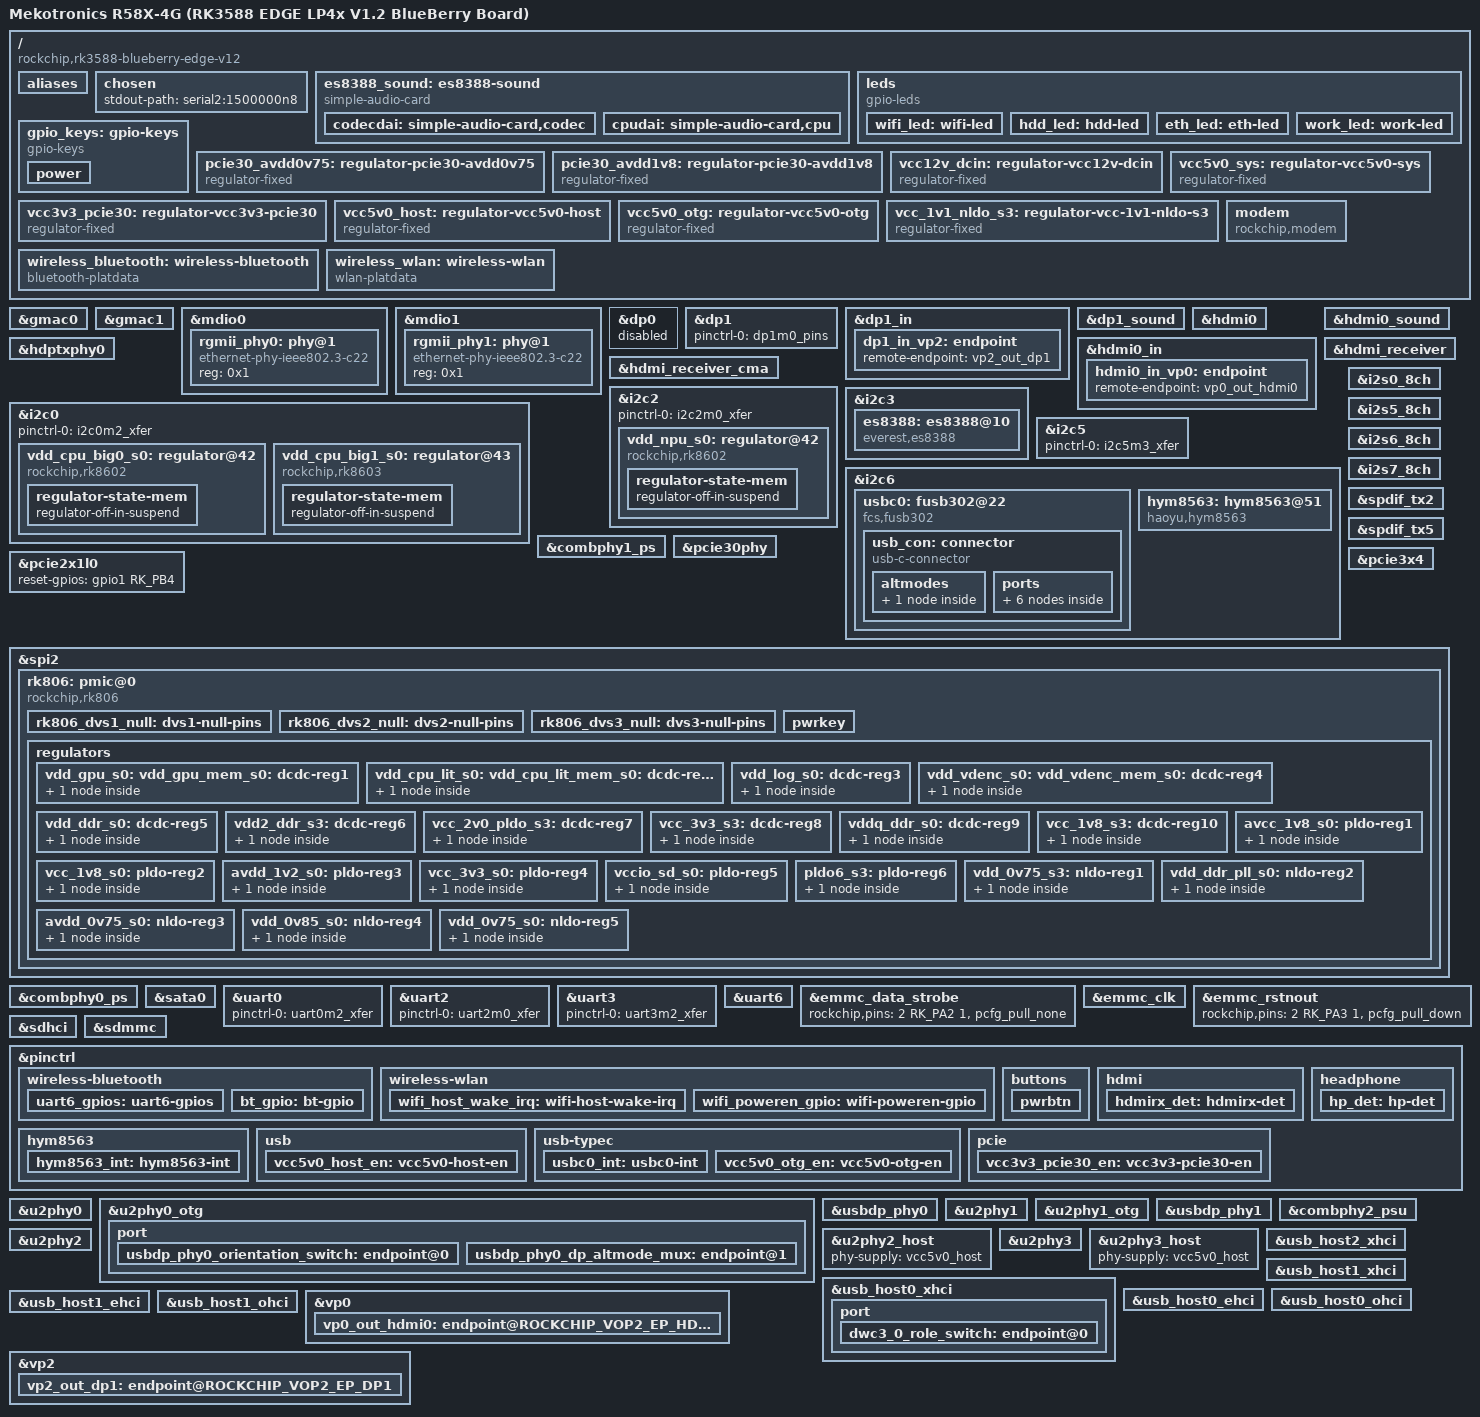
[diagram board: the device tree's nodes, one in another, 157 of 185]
// SPDX-License-Identifier: (GPL-2.0+ OR MIT)
/*
 * Copyright (c) 2026 Valentin Liu <valentinliu@icloud.com>
 */

/dts-v1/;

#include <dt-bindings/soc/rockchip,vop2.h>
#include "rk3588-blueberry.dtsi"

/ {	
	model = "Mekotronics R58X-4G (RK3588 EDGE LP4x V1.2 BlueBerry Board)";
	compatible = "rockchip,rk3588-blueberry-edge-v12", "rockchip,rk3588";

	aliases {
		ethernet0 = &gmac0;
		ethernet1 = &gmac1;
		mmc0 = &sdhci;
		mmc1 = &sdmmc;
		serial0 = &uart0;
		serial2 = &uart2;
		serial3 = &uart3;
		serial6 = &uart6;
	};

	chosen {
		stdout-path = "serial2:1500000n8";
	};

	es8388_sound: es8388-sound {
		compatible = "simple-audio-card";
		pinctrl-0 = <&hp_det>;
		pinctrl-names = "default";
		simple-audio-card,bitclock-master = <&cpudai>;
		simple-audio-card,format = "i2s";
		simple-audio-card,frame-master = <&cpudai>;
		simple-audio-card,mclk-fs = <256>;
		simple-audio-card,hp-det-gpios = <&gpio3 RK_PB2 GPIO_ACTIVE_HIGH>;
		simple-audio-card,name = "On-board Analog ES8388";
		simple-audio-card,widgets = "Microphone", "Main Mic",
					    "Microphone", "Headset Mic",
					    "Headphone", "Headphones",
					    "Speaker", "Speaker";

		simple-audio-card,routing = "Headphones", "LOUT1",
					    "Headphones", "ROUT1",
					    "Speaker", "LOUT2",
					    "Speaker", "ROUT2",
					    "LINPUT1", "Main Mic",
					    "LINPUT2", "Main Mic",
					    "RINPUT1", "Headset Mic",
					    "RINPUT2", "Headset Mic";

		simple-audio-card,pin-switches = "Headphones", "Speaker";

		codecdai: simple-audio-card,codec {
			sound-dai = <&es8388>;
			system-clock-frequency = <12288000>;
		};

		cpudai: simple-audio-card,cpu {
			sound-dai = <&i2s0_8ch>;
			system-clock-frequency = <12288000>;
		};
	};

	leds: leds {
		compatible = "gpio-leds";

		wifi_led: wifi-led {
			gpios = <&gpio3 RK_PC5 GPIO_ACTIVE_HIGH>;
			default-state = "off";
		};

		hdd_led: hdd-led {
			gpios = <&gpio3 RK_PC1 GPIO_ACTIVE_HIGH>;
			default-state = "off";
		};

		eth_led: eth-led {
			gpios = <&gpio3 RK_PC0 GPIO_ACTIVE_HIGH>;
			default-state = "off";
		};

		work_led: work-led {
			gpios = <&gpio3 RK_PB7 GPIO_ACTIVE_HIGH>;
			//linux,default-trigger = "heartbeat";
			default-state = "on";
		};
	};

	gpio_keys: gpio-keys {
		compatible = "gpio-keys";
		autorepeat;
		pinctrl-names = "default";
		pinctrl-0 = <&pwrbtn>;

		power {
			debounce-interval = <100>;
			gpios = <&gpio1 RK_PD3 GPIO_ACTIVE_LOW>;
			//gpios = <&gpio0 RK_PD5 GPIO_ACTIVE_LOW>;
			label = "GPIO Key Power";
			linux,code = <KEY_POWER>;
			wakeup-source;
		};
	};

	pcie30_avdd0v75: regulator-pcie30-avdd0v75 {
		compatible = "regulator-fixed";
		regulator-name = "pcie30_avdd0v75";
		regulator-boot-on;
		regulator-always-on;
		regulator-min-microvolt = <750000>;
		regulator-max-microvolt = <750000>;
		vin-supply = <&vdd_0v75_s0>;
	};

	pcie30_avdd1v8: regulator-pcie30-avdd1v8 {
		compatible = "regulator-fixed";
		regulator-name = "pcie30_avdd1v8";
		regulator-boot-on;
		regulator-always-on;
		regulator-min-microvolt = <1800000>;
		regulator-max-microvolt = <1800000>;
		vin-supply = <&avcc_1v8_s0>;
	};

	vcc12v_dcin: regulator-vcc12v-dcin {
		compatible = "regulator-fixed";
		regulator-name = "vcc12v_dcin";
		regulator-always-on;
		regulator-boot-on;
		regulator-min-microvolt = <12000000>;
		regulator-max-microvolt = <12000000>;
	};

	vcc3v3_pcie30: regulator-vcc3v3-pcie30 {
		compatible = "regulator-fixed";
		regulator-name = "vcc3v3_pcie30";
		regulator-min-microvolt = <3300000>;
		regulator-max-microvolt = <3300000>;
		enable-active-high;
		pinctrl-names = "default";
		pinctrl-0 = <&vcc3v3_pcie30_en>;
		gpios = <&gpio1 RK_PC4 GPIO_ACTIVE_HIGH>;    //hugsun gpio1_c4
		startup-delay-us = <10000>;
		vin-supply = <&vcc12v_dcin>;
	};

	vcc5v0_sys: regulator-vcc5v0-sys {
		compatible = "regulator-fixed";
		regulator-name = "vcc5v0_sys";
		regulator-always-on;
		regulator-boot-on;
		regulator-min-microvolt = <5000000>;
		regulator-max-microvolt = <5000000>;
		vin-supply = <&vcc12v_dcin>;
	};

	vcc5v0_host: regulator-vcc5v0-host {
		compatible = "regulator-fixed";
		regulator-name = "vcc5v0_host";
		regulator-boot-on;
		regulator-always-on;
		regulator-min-microvolt = <5000000>;
		regulator-max-microvolt = <5000000>;
		enable-active-high;
		gpio = <&gpio4 RK_PB0 GPIO_ACTIVE_HIGH>;
		vin-supply = <&vcc5v0_sys>;
		pinctrl-names = "default";
		pinctrl-0 = <&vcc5v0_host_en>;
	};

	vcc5v0_otg: regulator-vcc5v0-otg {
		compatible = "regulator-fixed";
		regulator-name = "vcc5v0_otg";
		regulator-min-microvolt = <5000000>;
		regulator-max-microvolt = <5000000>;
		enable-active-high;
		gpio = <&gpio4 RK_PA7 GPIO_ACTIVE_HIGH>;
		vin-supply = <&vcc5v0_sys>;
		pinctrl-names = "default";
		pinctrl-0 = <&vcc5v0_otg_en>;
	};

	vcc_1v1_nldo_s3: regulator-vcc-1v1-nldo-s3 {
		compatible = "regulator-fixed";
		regulator-name = "vcc_1v1_nldo_s3";
		regulator-always-on;
		regulator-boot-on;
		regulator-min-microvolt = <1100000>;
		regulator-max-microvolt = <1100000>;
		vin-supply = <&vcc5v0_sys>;
	};

	modem {
		compatible = "rockchip,modem";
		status = "okay";
		power-on_gpio = <&gpio0 RK_PD5 GPIO_ACTIVE_HIGH>;
		reset_gpio = <&gpio0 RK_PA0 GPIO_ACTIVE_HIGH>; //GPIO_C4
	};

	wireless_bluetooth: wireless-bluetooth {
		compatible = "bluetooth-platdata";
		clocks = <&hym8563>;
		clock-names = "ext_clock";
		uart_rts_gpios = <&gpio1 RK_PA2 GPIO_ACTIVE_LOW>;
		pinctrl-names = "default", "rts_gpio";
		pinctrl-0 = <&uart6m1_rtsn>, <&bt_gpio>;
		pinctrl-1 = <&uart6_gpios>;
		BT,reset_gpio    = <&gpio1 RK_PB2 GPIO_ACTIVE_HIGH>;
		BT,wake_gpio     = <&gpio1 RK_PA4 GPIO_ACTIVE_HIGH>;
		BT,wake_host_irq = <&gpio1 RK_PB0 GPIO_ACTIVE_HIGH>;
		status = "okay";
	};

	wireless_wlan: wireless-wlan {
		compatible = "wlan-platdata";
		wifi_chip_type = "ap6275p";
		pinctrl-names = "default";
		pinctrl-0 = <&wifi_host_wake_irq>, <&wifi_poweren_gpio>;
		WIFI,host_wake_irq = <&gpio1 RK_PA7 GPIO_ACTIVE_HIGH>;
		WIFI,poweren_gpio = <&gpio1 RK_PB1 GPIO_ACTIVE_HIGH>;
		status = "okay";
	};
};


/* Ethernet section */
&gmac0 {
	/* Use rgmii-rxid mode to disable rx delay inside Soc */
	phy-mode = "rgmii-rxid";
	clock_in_out = "output";

	snps,reset-gpio = <&gpio4 RK_PB3 GPIO_ACTIVE_LOW>;
	snps,reset-active-low;
	/* Reset time is 20ms, 100ms for rtl8211f */
	snps,reset-delays-us = <0 20000 100000>;

	pinctrl-names = "default";
	pinctrl-0 = <&gmac0_miim
		     &gmac0_tx_bus2
		     &gmac0_rx_bus2
		     &gmac0_rgmii_clk
		     &gmac0_rgmii_bus>;

	tx_delay = <0x44>;
	/* rx_delay = <0x4f>; */

	phy-handle = <&rgmii_phy0>;
	status = "okay";
};

&gmac1 {
	/* Use rgmii-rxid mode to disable rx delay inside Soc */
	phy-mode = "rgmii-rxid";
	clock_in_out = "output";

	snps,reset-gpio = <&gpio4 RK_PA2 GPIO_ACTIVE_LOW>;
	snps,reset-active-low;
	/* Reset time is 20ms, 100ms for rtl8211f */
	snps,reset-delays-us = <0 20000 100000>;

	pinctrl-names = "default";
	pinctrl-0 = <&gmac1_miim
		     &gmac1_tx_bus2
		     &gmac1_rx_bus2
		     &gmac1_rgmii_clk
		     &gmac1_rgmii_bus>;

	tx_delay = <0x42>;
	/* rx_delay = <0x4f>; */

	phy-handle = <&rgmii_phy1>;
	status = "okay";
};

&mdio0 {
	rgmii_phy0: phy@1 {
		compatible = "ethernet-phy-ieee802.3-c22";
		reg = <0x1>;
	};
};

&mdio1 {
	rgmii_phy1: phy@1 {
		compatible = "ethernet-phy-ieee802.3-c22";
		reg = <0x1>;
	};
};

/* Display (DisplayPort/HDMI) section */
// DisplayPort (DP)
&dp0 {
	status = "disabled";
};

&dp1 {
	pinctrl-0 = <&dp1m0_pins>;
	pinctrl-names = "default";
	status = "okay";
};

&dp1_in {
	dp1_in_vp2: endpoint {
		remote-endpoint = <&vp2_out_dp1>;
		status = "okay";
	};
};

&dp1_sound {
	status = "okay";
};

// HDMI out
&hdmi0 {
	enable-gpios = <&gpio4 RK_PB1 GPIO_ACTIVE_HIGH>;
	cec-enable = "true" ;
	status = "okay";
};

&hdmi0_in {
	hdmi0_in_vp0: endpoint {
		remote-endpoint = <&vp0_out_hdmi0>;
		status = "okay";
	};
};

&hdmi0_sound {
	status = "okay";
};

&hdptxphy0 {
	status = "okay";
};

// HDMI in
&hdmi_receiver_cma {
	status = "okay";
};

// Should work with at least 128MB cma reserved above.
&hdmi_receiver {
	#sound-dai-cells = <1>;
	hpd-gpios = <&gpio1 RK_PD5 GPIO_ACTIVE_LOW>;   //gpio1_d5
	pinctrl-names = "default";
	pinctrl-0 = <&hdmim1_rx_cec &hdmim1_rx_scl &hdmim1_rx_sda &hdmim1_rx_hpdin &hdmirx_det>;
	status = "okay";
};


/* I2C Controller section */
&i2c0 {
	status = "okay";
	pinctrl-names = "default";
	pinctrl-0 = <&i2c0m2_xfer>;

	vdd_cpu_big0_s0: regulator@42 {
		compatible = "rockchip,rk8602";
		reg = <0x42>;
		fcs,suspend-voltage-selector = <1>;
		regulator-name = "vdd_cpu_big0_s0";
		regulator-always-on;
		regulator-boot-on;
		regulator-min-microvolt = <550000>;
		regulator-max-microvolt = <1050000>;
		regulator-ramp-delay = <2300>;
		vin-supply = <&vcc5v0_sys>;

		regulator-state-mem {
			regulator-off-in-suspend;
		};
	};

	vdd_cpu_big1_s0: regulator@43 {
		compatible = "rockchip,rk8603", "rockchip,rk8602";
		reg = <0x43>;
		fcs,suspend-voltage-selector = <1>;
		regulator-name = "vdd_cpu_big1_s0";
		regulator-always-on;
		regulator-boot-on;
		regulator-min-microvolt = <550000>;
		regulator-max-microvolt = <1050000>;
		regulator-ramp-delay = <2300>;
		vin-supply = <&vcc5v0_sys>;

		regulator-state-mem {
			regulator-off-in-suspend;
		};
	};
};

&i2c2 {
	pinctrl-names = "default";
	pinctrl-0 = <&i2c2m0_xfer>;
	status = "okay";

	vdd_npu_s0: regulator@42 {
		compatible = "rockchip,rk8602";
		reg = <0x42>;
		fcs,suspend-voltage-selector = <1>;
		regulator-name = "vdd_npu_s0";
		vin-supply = <&vcc5v0_sys>;
		regulator-min-microvolt = <550000>;
		regulator-max-microvolt = <950000>;
		regulator-enable-ramp-delay = <500>;
		regulator-ramp-delay = <2300>;
		regulator-boot-on;
		regulator-always-on;

		regulator-state-mem {
			regulator-off-in-suspend;
		};
	};
};

&i2c3 {
	status = "okay";

	es8388: es8388@10 {
		compatible = "everest,es8388", "everest,es8323";
		reg = <0x10>;
		assigned-clocks = <&cru I2S0_8CH_MCLKOUT>;
		assigned-clock-rates = <12288000>;
		clocks = <&cru I2S0_8CH_MCLKOUT>;
		AVDD-supply = <&vcc_1v8_s0>;
		DVDD-supply = <&vcc_1v8_s0>;
		HPVDD-supply = <&vcc_3v3_s0>;
		PVDD-supply = <&vcc_3v3_s0>;
		#sound-dai-cells = <0>;
		status = "okay";
	};
};

&i2c5 {
	pinctrl-names = "default";
	pinctrl-0 = <&i2c5m3_xfer>;
	status = "okay";
};

&i2c6 {
	status = "okay";

	usbc0: fusb302@22 {
		compatible = "fcs,fusb302";
		reg = <0x22>;
		interrupt-parent = <&gpio3>;
		interrupts = <RK_PC7 IRQ_TYPE_LEVEL_LOW>;
		pinctrl-names = "default";
		pinctrl-0 = <&usbc0_int>;
		vbus-supply = <&vcc5v0_otg>;
		status = "okay";

		usb_con: connector {
			compatible = "usb-c-connector";
			label = "USB-C";
			data-role = "dual";
			power-role = "dual";
			try-power-role = "sink";
			op-sink-microwatt = <1000000>;
			sink-pdos = <PDO_FIXED(5000, 1000, PDO_FIXED_USB_COMM)>;
			source-pdos = <PDO_FIXED(5000, 3000, PDO_FIXED_USB_COMM)>;

			altmodes {
				#address-cells = <1>;
				#size-cells = <0>;

				altmode@0 {
					reg = <0>;
					svid = <0xff01>;
					vdo = <0xffffffff>;
				};
			};

			ports {
				#address-cells = <1>;
				#size-cells = <0>;

				port@0 {
					reg = <0>;
					usbc0_orien_sw: endpoint {
						remote-endpoint = <&usbdp_phy0_orientation_switch>;
					};
				};
				
				port@1 {
					reg = <1>;
					usbc0_role_sw: endpoint@0 {
						remote-endpoint = <&dwc3_0_role_switch>;
					};
				};

				port@2 {
					reg = <2>;
					dp_altmode_mux: endpoint {
						remote-endpoint = <&usbdp_phy0_dp_altmode_mux>;
					};
				};
			};
		};
	};

	hym8563: hym8563@51 {
		compatible = "haoyu,hym8563";
		reg = <0x51>;
		#clock-cells = <0>;
		clock-frequency = <32768>;
		clock-output-names = "hym8563";
		pinctrl-names = "default";
		pinctrl-0 = <&hym8563_int>;
		interrupt-parent = <&gpio0>;
		interrupts = <RK_PB2 IRQ_TYPE_LEVEL_LOW>;
		wakeup-source;
	};
};


/* Audio section */
&i2s0_8ch {
	pinctrl-names = "default";
	pinctrl-0 = <&i2s0_lrck
		     &i2s0_mclk
		     &i2s0_sclk
		     &i2s0_sdi0
		     &i2s0_sdo0>;
	status = "okay";
};

//hdmi01 sound
&i2s5_8ch {
	status = "okay";
};

//hdmi02 sound
&i2s6_8ch {
	status = "okay";
};

//hdmiin sound
&i2s7_8ch {
	status = "okay";
};

&spdif_tx2 {
	status = "okay";
};

&spdif_tx5 {
	status = "okay";
};


/* PCIe section */
// AP6275P Wi-Fi
&combphy1_ps {
	status = "okay";
};

&pcie2x1l0 {
	reset-gpios = <&gpio1 RK_PB4 GPIO_ACTIVE_HIGH>;
	status = "okay";
};

// NVME M.2 M-Key
&pcie30phy {
	status = "okay";
};

&pcie3x4 {
	reset-gpios = <&gpio4 RK_PB6 GPIO_ACTIVE_HIGH>;
	vpcie3v3-supply = <&vcc3v3_pcie30>;
	status = "okay";
};


/* PMIC section */
&spi2 {
	status = "okay";
	assigned-clocks = <&cru CLK_SPI2>;
	assigned-clock-rates = <200000000>;
	pinctrl-names = "default";
	pinctrl-0 = <&spi2m2_cs0 &spi2m2_pins>;
	num-cs = <1>;

	rk806: pmic@0 {
		compatible = "rockchip,rk806";
		reg = <0x0>;

		spi-max-frequency = <1000000>;
		system-power-controller;

		interrupt-parent = <&gpio0>;
		interrupts = <7 IRQ_TYPE_LEVEL_LOW>;

		pinctrl-names = "default";
		pinctrl-0 = <&pmic_pins>, <&rk806_dvs1_null>,
			    <&rk806_dvs2_null>, <&rk806_dvs3_null>;

		/* 2800mv-3500mv */
		low_voltage_threshold = <3000>;
		/* 2700mv-3400mv */
		shutdown_voltage_threshold = <2700>;
		/* 140 160 */
		shutdown_temperture_threshold = <160>;
		hotdie_temperture_threshold = <115>;

		/* 0: restart PMU;
		 * 1: reset all the power off reset registers,
		 *    forcing the state to switch to ACTIVE mode;
		 * 2: Reset all the power off reset registers,
		 *    forcing the state to switch to ACTIVE mode,
		 *    and simultaneously pull down the RESETB PIN for 5mS before releasing
		 */
		pmic-reset-func = <1>;

		vcc1-supply = <&vcc5v0_sys>;
		vcc2-supply = <&vcc5v0_sys>;
		vcc3-supply = <&vcc5v0_sys>;
		vcc4-supply = <&vcc5v0_sys>;
		vcc5-supply = <&vcc5v0_sys>;
		vcc6-supply = <&vcc5v0_sys>;
		vcc7-supply = <&vcc5v0_sys>;
		vcc8-supply = <&vcc5v0_sys>;
		vcc9-supply = <&vcc5v0_sys>;
		vcc10-supply = <&vcc5v0_sys>;
		vcc11-supply = <&vcc_2v0_pldo_s3>;
		vcc12-supply = <&vcc5v0_sys>;
		vcc13-supply = <&vcc_1v1_nldo_s3>;
		vcc14-supply = <&vcc_1v1_nldo_s3>;
		vcca-supply = <&vcc5v0_sys>;

		rk806_dvs1_null: dvs1-null-pins {
			pins = "gpio_pwrctrl1";
			function = "pin_fun0";
		};

		rk806_dvs2_null: dvs2-null-pins {
			pins = "gpio_pwrctrl2";
			function = "pin_fun0";
		};

		rk806_dvs3_null: dvs3-null-pins {
			pins = "gpio_pwrctrl3";
			function = "pin_fun0";
		};

		pwrkey {
			status = "okay";
		};

		regulators {
			vdd_gpu_s0: vdd_gpu_mem_s0: dcdc-reg1 {
				regulator-name = "vdd_gpu_s0";
				regulator-boot-on;
				regulator-min-microvolt = <550000>;
				regulator-max-microvolt = <950000>;
				regulator-ramp-delay = <12500>;
				regulator-enable-ramp-delay = <400>;
				regulator-state-mem {
					regulator-off-in-suspend;
				};
			};

			vdd_cpu_lit_s0: vdd_cpu_lit_mem_s0: dcdc-reg2 {
				regulator-name = "vdd_cpu_lit_s0";
				regulator-always-on;
				regulator-boot-on;
				regulator-init-microvolt = <800000>;
				regulator-min-microvolt = <550000>;
				regulator-max-microvolt = <950000>;
				regulator-ramp-delay = <12500>;
				regulator-state-mem {
					regulator-off-in-suspend;
				};
			};

			vdd_log_s0: dcdc-reg3 {
				regulator-name = "vdd_log_s0";
				regulator-always-on;
				regulator-boot-on;
				regulator-min-microvolt = <675000>;
				regulator-max-microvolt = <800000>;
				regulator-ramp-delay = <12500>;
				regulator-state-mem {
					regulator-off-in-suspend;
					regulator-suspend-microvolt = <750000>;
				};
			};

			vdd_vdenc_s0: vdd_vdenc_mem_s0: dcdc-reg4 {
				regulator-name = "vdd_vdenc_s0";
				regulator-always-on;
				regulator-boot-on;
				regulator-min-microvolt = <550000>;
				regulator-max-microvolt = <950000>;
				regulator-init-microvolt = <750000>;
				regulator-ramp-delay = <12500>;
				regulator-state-mem {
					regulator-off-in-suspend;
				};
			};

			vdd_ddr_s0: dcdc-reg5 {
				regulator-name = "vdd_ddr_s0";
				regulator-always-on;
				regulator-boot-on;
				regulator-min-microvolt = <675000>;
				regulator-max-microvolt = <900000>;
				regulator-ramp-delay = <12500>;
				regulator-state-mem {
					regulator-off-in-suspend;
					regulator-suspend-microvolt = <850000>;
				};
			};

			vdd2_ddr_s3: dcdc-reg6 {
				regulator-name = "vdd2_ddr_s3";
				regulator-always-on;
				regulator-boot-on;
				regulator-state-mem {
					regulator-on-in-suspend;
				};
			};

			vcc_2v0_pldo_s3: dcdc-reg7 {
				regulator-name = "vdd_2v0_pldo_s3";
				regulator-always-on;
				regulator-boot-on;
				regulator-min-microvolt = <2000000>;
				regulator-max-microvolt = <2000000>;
				regulator-state-mem {
					regulator-on-in-suspend;
					regulator-suspend-microvolt = <2000000>;
				};
			};

			vcc_3v3_s3: dcdc-reg8 {
				regulator-name = "vcc_3v3_s3";
				regulator-always-on;
				regulator-boot-on;
				regulator-min-microvolt = <3300000>;
				regulator-max-microvolt = <3300000>;
				regulator-state-mem {
					regulator-on-in-suspend;
					regulator-suspend-microvolt = <3300000>;
				};
			};

			vddq_ddr_s0: dcdc-reg9 {
				regulator-name = "vddq_ddr_s0";
				regulator-always-on;
				regulator-boot-on;
				regulator-state-mem {
					regulator-off-in-suspend;
				};
			};

			vcc_1v8_s3: dcdc-reg10 {
				regulator-name = "vcc_1v8_s3";
				regulator-always-on;
				regulator-boot-on;
				regulator-min-microvolt = <1800000>;
				regulator-max-microvolt = <1800000>;
				regulator-state-mem {
					regulator-on-in-suspend;
					regulator-suspend-microvolt = <1800000>;
				};
			};

			avcc_1v8_s0: pldo-reg1 {
				regulator-name = "avcc_1v8_s0";
				regulator-always-on;
				regulator-boot-on;
				regulator-min-microvolt = <1800000>;
				regulator-max-microvolt = <1800000>;
				regulator-state-mem {
					regulator-off-in-suspend;
					regulator-suspend-microvolt = <1800000>;
				};
			};

			vcc_1v8_s0: pldo-reg2 {
				regulator-name = "vcc_1v8_s0";
				regulator-always-on;
				regulator-boot-on;
				regulator-min-microvolt = <1800000>;
				regulator-max-microvolt = <1800000>;
				regulator-state-mem {
					regulator-off-in-suspend;
					regulator-suspend-microvolt = <1800000>;
				};
			};

			avdd_1v2_s0: pldo-reg3 {
				regulator-name = "avdd_1v2_s0";
				regulator-always-on;
				regulator-boot-on;
				regulator-min-microvolt = <1200000>;
				regulator-max-microvolt = <1200000>;
				regulator-state-mem {
					regulator-off-in-suspend;
				};
			};

			vcc_3v3_s0: pldo-reg4 {
				regulator-name = "vcc_3v3_s0";
				regulator-always-on;
				regulator-boot-on;
				regulator-min-microvolt = <3300000>;
				regulator-max-microvolt = <3300000>;
				regulator-state-mem {
					regulator-off-in-suspend;
				};
			};

			vccio_sd_s0: pldo-reg5 {
				regulator-name = "vccio_sd_s0";
				regulator-always-on;
				regulator-boot-on;
				regulator-min-microvolt = <1800000>;
				regulator-max-microvolt = <3300000>;
				regulator-state-mem {
					regulator-off-in-suspend;
				};
			};

			pldo6_s3: pldo-reg6 {
				regulator-name = "pldo6_s3";
				regulator-always-on;
				regulator-boot-on;
				regulator-min-microvolt = <1800000>;
				regulator-max-microvolt = <1800000>;
				regulator-state-mem {
					regulator-on-in-suspend;
					regulator-suspend-microvolt = <1800000>;
				};
			};

			vdd_0v75_s3: nldo-reg1 {
				regulator-name = "vdd_0v75_s3";
				regulator-always-on;
				regulator-boot-on;
				regulator-min-microvolt = <750000>;
				regulator-max-microvolt = <750000>;
				regulator-state-mem {
					regulator-on-in-suspend;
					regulator-suspend-microvolt = <750000>;
				};
			};

			vdd_ddr_pll_s0: nldo-reg2 {
				regulator-name = "vdd_ddr_pll_s0";
				regulator-always-on;
				regulator-boot-on;
				regulator-min-microvolt = <850000>;
				regulator-max-microvolt = <850000>;
				regulator-state-mem {
					regulator-off-in-suspend;
					regulator-suspend-microvolt = <850000>;
				};
			};

			avdd_0v75_s0: nldo-reg3 {
				regulator-name = "avdd_0v75_s0";
				regulator-always-on;
				regulator-boot-on;
				/*
				 * The schematic mentions that actual setting
				 * should be 0.8375V. RK3588 datasheet specifies
				 * maximum as 0.825V. So we set datasheet max
				 * here.
				 */
				regulator-min-microvolt = <825000>;
				regulator-max-microvolt = <825000>;

				regulator-state-mem {
					regulator-off-in-suspend;
				};
			};

			vdd_0v85_s0: nldo-reg4 {
				regulator-name = "vdd_0v85_s0";
				regulator-always-on;
				regulator-boot-on;
				regulator-min-microvolt = <850000>;
				regulator-max-microvolt = <850000>;
				regulator-state-mem {
					regulator-off-in-suspend;
				};
			};

			vdd_0v75_s0: nldo-reg5 {
				regulator-name = "vdd_0v75_s0";
				regulator-always-on;
				regulator-boot-on;
				regulator-min-microvolt = <750000>;
				regulator-max-microvolt = <750000>;

				regulator-state-mem {
					regulator-off-in-suspend;
				};
			};
		};
	};
};

&vdd_log_s0 {
	//fox.luo@2022.05.26 don't wake up
    regulator-state-mem {
        regulator-on-in-suspend;
        regulator-suspend-microvolt = <750000>;
    };
};

&vdd_vdenc_s0 {
	regulator-init-microvolt = <750000>;
};


/* SATA Controller section */
// SATA PHY
&combphy0_ps {
	status = "okay";
};

// SATA 3.0
&sata0 {
	status = "okay";
};


/* UART section */
// RS485
&uart0 {
	status = "okay";
	pinctrl-names = "default";
	pinctrl-0 = <&uart0m2_xfer>;
};

// debug port
&uart2 {
	status = "okay";
	pinctrl-0 = <&uart2m0_xfer>;
};

// RS232
&uart3 {
	status = "okay";
	pinctrl-names = "default";
	pinctrl-0 = <&uart3m2_xfer>;
};

// AP6275P Bluetooth
&uart6 {
	status = "okay";
	pinctrl-names = "default";
	pinctrl-0 = <&uart6m1_xfer &uart6m1_ctsn &uart6m1_rtsn>;
};

/* MMC section */
&emmc_data_strobe {
	rockchip,pins =
		/* emmc_data_strobe */
		<2 RK_PA2 1 &pcfg_pull_none>;
};

/* this is important! */
&emmc_clk {
	rockchip,pins =
		/* emmc_clkout */
		<2 RK_PA1 1 &pcfg_pull_down_drv_level_1>;
};

&emmc_rstnout {
	rockchip,pins =
		/* emmc_rstn */
		<2 RK_PA3 1 &pcfg_pull_down>;
};

// eMMC FSEIASLD-xxG
&sdhci {
	bus-width = <8>;
	max-frequency = <200000000>;
	mmc-hs400-1_8v;
	mmc-hs400-enhanced-strobe;
	full-pwr-cycle-in-suspend;
	no-sdio;
	no-sd;
	non-removable;
	status = "okay";
};

// SD Card
&sdmmc {
	bus-width = <4>;
	max-frequency = <150000000>;
	cap-mmc-highspeed;
	cap-sd-highspeed;
	disable-wp;
	sd-uhs-sdr104;
	vqmmc-supply = <&vccio_sd_s0>;
	no-sdio;
	no-mmc;
	status = "okay";
};


/* PIN Control section */
&pinctrl {
	wireless-bluetooth {
		uart6_gpios: uart6-gpios {
			rockchip,pins = <1 RK_PA2 RK_FUNC_GPIO &pcfg_pull_none>;
		};

		bt_gpio: bt-gpio {
			rockchip,pins =
				<1 RK_PB2 RK_FUNC_GPIO &pcfg_pull_none>,
				<1 RK_PB0 RK_FUNC_GPIO &pcfg_pull_up>,
				<1 RK_PA4 RK_FUNC_GPIO &pcfg_pull_down>;
		};
	};

	wireless-wlan {
		wifi_host_wake_irq: wifi-host-wake-irq {
			rockchip,pins = <1 RK_PA7 RK_FUNC_GPIO &pcfg_pull_down>;
		};

		wifi_poweren_gpio: wifi-poweren-gpio {
			rockchip,pins = <1 RK_PB1 RK_FUNC_GPIO &pcfg_pull_up>;
		};
	};

	buttons {
		pwrbtn: pwrbtn {
			rockchip,pins = <1 RK_PD3 RK_FUNC_GPIO &pcfg_pull_up>;
			//rockchip,pins = <0 RK_PD5 RK_FUNC_GPIO &pcfg_pull_up>;
		};
	};

	hdmi {
		hdmirx_det: hdmirx-det {
			rockchip,pins = <1 RK_PD5 RK_FUNC_GPIO &pcfg_pull_up>;
		};
	};

	headphone {
		hp_det: hp-det {
			rockchip,pins = <3 RK_PB2 RK_FUNC_GPIO &pcfg_pull_none>;
		};
	};

	hym8563 {
		hym8563_int: hym8563-int {
			rockchip,pins = <0 RK_PB2 RK_FUNC_GPIO &pcfg_pull_up>;
		};
	};

	usb {
		vcc5v0_host_en: vcc5v0-host-en {
			rockchip,pins = <4 RK_PB0 RK_FUNC_GPIO &pcfg_pull_none>;
		};

	};

	usb-typec {
		usbc0_int: usbc0-int {
			rockchip,pins = <3 RK_PC7 RK_FUNC_GPIO &pcfg_pull_up>;
		};

		vcc5v0_otg_en: vcc5v0-otg-en {
			rockchip,pins = <4 RK_PA7 RK_FUNC_GPIO &pcfg_pull_none>;
		};
	};

	pcie {
		vcc3v3_pcie30_en: vcc3v3-pcie30-en {
			rockchip,pins = <1 RK_PC4 RK_FUNC_GPIO &pcfg_pull_up>;
		};
	};
};

/* USB section */
/* USB PHY section */
// USB3.0 Type-C (OTG)
&u2phy0 {
	status = "okay";
};

&u2phy0_otg {
	orientation-switch;
	svid = <0xff01>;
	sbu1-dc-gpios = <&gpio0 RK_PC6 GPIO_ACTIVE_HIGH>;
	sbu2-dc-gpios = <&gpio0 RK_PD3 GPIO_ACTIVE_HIGH>;
	status = "okay";

	port {
		#address-cells = <1>;
		#size-cells = <0>;
		usbdp_phy0_orientation_switch: endpoint@0 {
			reg = <0>;
			remote-endpoint = <&usbc0_orien_sw>;
		};

		usbdp_phy0_dp_altmode_mux: endpoint@1 {
			reg = <1>;
			remote-endpoint = <&dp_altmode_mux>;
		};
	};
};

&usbdp_phy0 {
	status = "okay";
};

// Onboard 4-Pin USB Port (Host)
&u2phy1 {
	status = "okay";
};

&u2phy1_otg {
	maximum-speed = "high-speed";
	phy-supply = <&vcc5v0_host>;
	status = "okay";
};

&usbdp_phy1 {
	// rockchip,dp-lane-mux = < 0 1 2 3 >;
	status = "okay";
};

// USB3.0 Type-A (Host)
&combphy2_psu {
	status = "okay";
};

// USB2.0 Type-A
&u2phy2 {
	status = "okay";
};

&u2phy2_host {
	phy-supply = <&vcc5v0_host>;
	status = "okay";
};

&u2phy3 {
	status = "okay";
};

&u2phy3_host {
	phy-supply = <&vcc5v0_host>;
	status = "okay";
};

/* USB Controller section */
// USB3.0 Type-C (OTG)
&usb_host0_xhci {
	dr_mode = "otg";
	usb-role-switch;
	status = "okay";

	port {
		#address-cells = <1>;
		#size-cells = <0>;
		dwc3_0_role_switch: endpoint@0 {
			reg = <0>;
			remote-endpoint = <&usbc0_role_sw>;
		};
	};
};

// USB3.0 Type-A (Host)
&usb_host2_xhci {
	status = "okay";
};

// Onboard 4-Pin USB Port (Host)
&usb_host1_xhci {
	dr_mode = "host";
	maximum-speed = "high-speed";
	status = "okay";
};

// USB2.0 Type-A
&usb_host0_ehci {
	status = "okay";
};

&usb_host0_ohci {
	status = "okay";
};

&usb_host1_ehci {
	status = "okay";
};

&usb_host1_ohci {
	status = "okay";
};


/* Rockchip Video Processor section */
// HDMI
&vp0 {
	vp0_out_hdmi0: endpoint@ROCKCHIP_VOP2_EP_HDMI0 {
		reg = <ROCKCHIP_VOP2_EP_HDMI0>;
		remote-endpoint = <&hdmi0_in_vp0>;
	};
};

// DisplayPort (DP)
&vp2 {
	vp2_out_dp1: endpoint@ROCKCHIP_VOP2_EP_DP1 {
		reg = <ROCKCHIP_VOP2_EP_DP1>;
		remote-endpoint = <&dp1_in_vp2>;
	};
};

